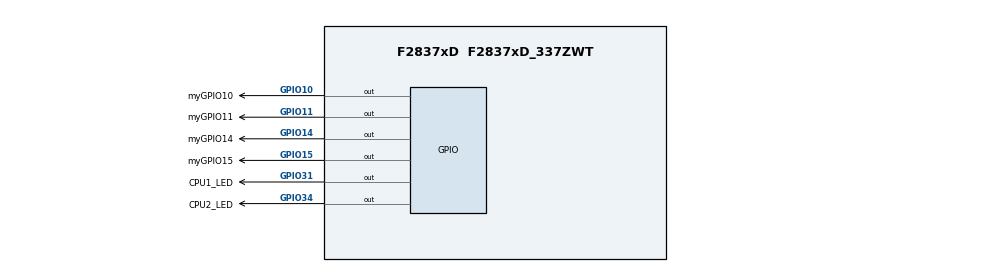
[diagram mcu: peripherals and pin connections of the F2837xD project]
/**
 * @cliArgs --device "F2837xD" --package "F2837xD_337ZWT" --part "F2837xD_337ZWT" --context "CPU1" --product "C2000WARE@4.03.00.00"
 * @versions {"tool":"1.15.999+71"}
 */

/**
 * Import the modules used in this configuration.
 */
const gpio  = scripting.addModule("/driverlib/gpio.js", {}, false);
const gpio1 = gpio.addInstance();
const gpio2 = gpio.addInstance();
const gpio3 = gpio.addInstance();
const gpio4 = gpio.addInstance();
const gpio5 = gpio.addInstance();
const gpio6 = gpio.addInstance();
const CMD   = scripting.addModule("/utilities/cmd_tool/cmd_syscfg/source/CMD");
const CMD1  = CMD.addInstance();

/**
 * Write custom configuration values to the imported modules.
 */
gpio1.$name           = "CPU1_LED";
gpio1.direction       = "GPIO_DIR_MODE_OUT";
gpio1.gpioPin.$assign = "GPIO31";

gpio2.$name           = "CPU2_LED";
gpio2.controllerCore  = "GPIO_CORE_CPU2";
gpio2.direction       = "GPIO_DIR_MODE_OUT";
gpio2.gpioPin.$assign = "GPIO34";

gpio3.$name           = "myGPIO10";
gpio3.direction       = "GPIO_DIR_MODE_OUT";
gpio3.controllerCore  = "GPIO_CORE_CPU2";
gpio3.gpioPin.$assign = "GPIO10";

gpio4.$name           = "myGPIO11";
gpio4.controllerCore  = "GPIO_CORE_CPU2";
gpio4.gpioPin.$assign = "GPIO11";

gpio5.$name           = "myGPIO14";
gpio5.gpioPin.$assign = "GPIO14";

gpio6.$name           = "myGPIO15";
gpio6.direction       = "GPIO_DIR_MODE_OUT";
gpio6.gpioPin.$assign = "GPIO15";

CMD.activateCMD = true;

CMD1.$name                               = "CMD0";
CMD1.sectionMemory_text                  = ["FLASHB","FLASHC","FLASHD","FLASHE"];
CMD1.sectionAlignEnable_text             = true;
CMD1.sectionMemory_ramfunc               = ["FLASHD"];
CMD1.sectionRunFromDifferentAddr_ramfunc = true;
CMD1.sectionRun_ramfunc                  = ["RAMLS0"];
CMD1.sectionAlignEnable_ramfunc          = true;
CMD1.sectionMemory_ovly                  = ["FLASHA"];
CMD1.sectionAlignEnable_ovly             = true;
CMD1.sectionMemory_cinit                 = ["FLASHA"];
CMD1.sectionAlignEnable_cinit            = true;
CMD1.sectionMemory_stack                 = ["RAMM1"];
CMD1.sectionMemory_init_array            = ["FLASHB"];
CMD1.sectionAlignEnable_init_array       = true;
CMD1.sectionMemory_bss                   = ["RAMLS5"];
CMD1.sectionMemory_const                 = ["FLASHF"];
CMD1.sectionAlignEnable_const            = true;
CMD1.sectionMemory_data                  = ["RAMLS5"];
CMD1.sectionMemory_switch                = ["FLASHA"];
CMD1.sectionAlignEnable_switch           = true;
CMD1.sectionMemory_sysmem                = ["RAMLS5"];
CMD1.sectionAlignEnable_binit            = true;
CMD1.sectionMemory_binit                 = ["FLASHA"];
